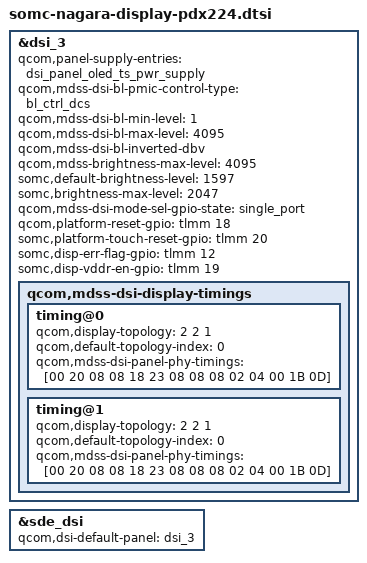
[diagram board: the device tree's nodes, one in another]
#include "dsi-panel-s6e3fac-amb609bn01-fhd_plus.dtsi"

&dsi_3 {
	qcom,panel-supply-entries = <&dsi_panel_oled_ts_pwr_supply>;
	qcom,mdss-dsi-bl-pmic-control-type = "bl_ctrl_dcs";
	qcom,mdss-dsi-bl-min-level = <1>;
	qcom,mdss-dsi-bl-max-level = <4095>;
	qcom,mdss-dsi-bl-inverted-dbv;
	qcom,mdss-brightness-max-level = <4095>;
	somc,default-brightness-level = <1597>;
	somc,brightness-max-level = <2047>;
	qcom,mdss-dsi-mode-sel-gpio-state = "single_port";

	qcom,platform-reset-gpio = <&tlmm 18 0>;
	somc,platform-touch-reset-gpio = <&tlmm 20 0>;
	somc,disp-err-flag-gpio = <&tlmm 12 0>;
	somc,disp-vddr-en-gpio = <&tlmm 19 0>;

	qcom,mdss-dsi-display-timings {
		timing@0 {
			qcom,display-topology = <2 2 1>;
			qcom,default-topology-index = <0>;
			qcom,mdss-dsi-panel-phy-timings = [00 20 08 08 18 23 08 08 08 02 04 00 1B 0D];
		};
		timing@1 {
			qcom,display-topology = <2 2 1>;
			qcom,default-topology-index = <0>;
			qcom,mdss-dsi-panel-phy-timings = [00 20 08 08 18 23 08 08 08 02 04 00 1B 0D];
		};
	};
};

&sde_dsi {
	qcom,dsi-default-panel = <&dsi_3>;
};

